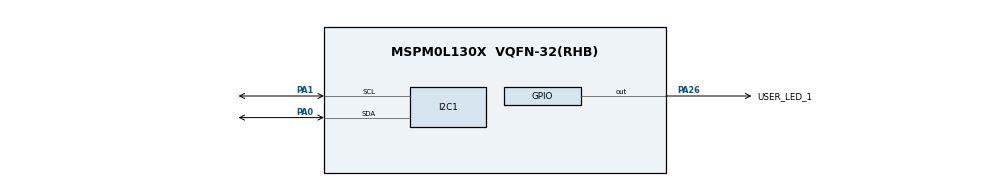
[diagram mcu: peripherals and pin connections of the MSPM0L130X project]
// @cliArgs --device "MSPM0L130X" --package "VQFN-32(RHB)" --part "Default"
// @cliArgs --board /ti/boards/LP_MSPM0L1306 --rtos nortos

/**
 * Import the modules used in this configuration.
 */
const Board  = scripting.addModule("/ti/driverlib/Board");
const GPIO   = scripting.addModule("/ti/driverlib/GPIO", {}, false);
const GPIO1  = GPIO.addInstance();
const I2C    = scripting.addModule("/ti/driverlib/I2C", {}, false);
const I2C1   = I2C.addInstance();
const SYSCTL = scripting.addModule("/ti/driverlib/SYSCTL");

/**
 * Write custom configuration values to the imported modules.
 */
Board.configureUnused = true;

GPIO1.$name                                 = "GPIO_LEDS";
GPIO1.port                                  = "PORTA";
GPIO1.associatedPins[0].$name               = "USER_LED_1";
GPIO1.associatedPins[0].assignedPortSegment = "Upper";
GPIO1.associatedPins[0].assignedPin         = "26";
GPIO1.associatedPins[0].pin.$assign         = "PA26";

I2C1.$name                     = "I2C";
I2C1.basicControllerBusSpeed   = 400000;
I2C1.advControllerTXFIFOTRIG   = "BYTES_1";
I2C1.basicTargetAddress        = 0x48;
I2C1.basicEnableTarget         = true;
I2C1.advAnalogGlitchFilter     = "DISABLED";
I2C1.peripheral.$assign        = "I2C0";
I2C1.peripheral.sdaPin.$assign = "PA0";
I2C1.peripheral.sclPin.$assign = "PA1";

SYSCTL.powerPolicy        = "STOP0";
SYSCTL.peripheral.$assign = "SYSCTL";
SYSCTL.clockTreeEn = true;
